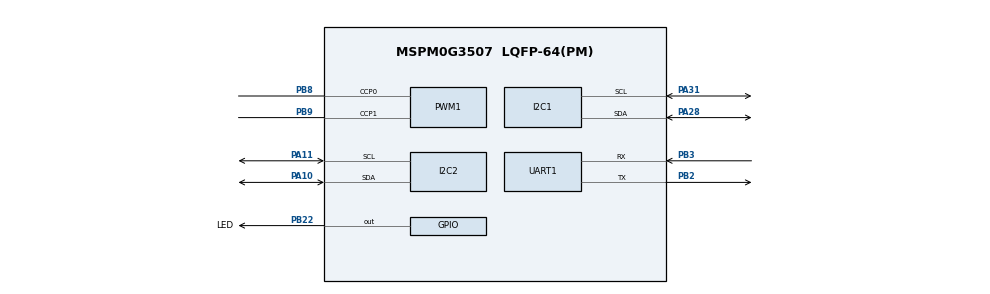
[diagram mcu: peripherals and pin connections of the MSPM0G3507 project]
/**
 * MSPM0G3507 gimbal receiver.
 * PB8/PB9 output 50Hz servo PWM, PB3 receives K230 UART frames.
 */
//@cliArgs --device "MSPM0G350X" --package "LQFP-64(PM)" --part "Default"
//@v2CliArgs --device "MSPM0G3507" --package "LQFP-64(PM)"

const GPIO   = scripting.addModule("/ti/driverlib/GPIO", {}, false);
const GPIO1  = GPIO.addInstance();
const PWM    = scripting.addModule("/ti/driverlib/PWM", {}, false);
const PWM1   = PWM.addInstance();
const SYSCTL = scripting.addModule("/ti/driverlib/SYSCTL");
const I2C    = scripting.addModule("/ti/driverlib/I2C", {}, false);
const I2C1   = I2C.addInstance();
const I2C2   = I2C.addInstance();
const UART   = scripting.addModule("/ti/driverlib/UART", {}, false);
const UART1  = UART.addInstance();
const Board  = scripting.addModule("/ti/driverlib/Board", {}, false);

GPIO1.$name                         = "GPIO";
GPIO1.associatedPins[0].$name       = "LED";
GPIO1.associatedPins[0].pin.$assign = "PB22";

PWM1.$name                              = "SERVO_PWM";
PWM1.timerStartTimer                    = true;
PWM1.timerCount                         = 9999;
PWM1.clockPrescale                      = 64;
PWM1.peripheral.ccp0Pin.$assign         = "PB8";
PWM1.peripheral.ccp1Pin.$assign         = "PB9";
PWM1.PWM_CHANNEL_0.$name                = "ti_driverlib_pwm_PWMTimerCC0";
PWM1.PWM_CHANNEL_1.$name                = "ti_driverlib_pwm_PWMTimerCC1";
PWM1.ccp0PinConfig.$name                = "ti_driverlib_gpio_GPIOPinGeneric0";
PWM1.ccp0PinConfig.direction            = scripting.forceWrite("OUTPUT");
PWM1.ccp0PinConfig.hideOutputInversion  = scripting.forceWrite(false);
PWM1.ccp0PinConfig.onlyInternalResistor = scripting.forceWrite(false);
PWM1.ccp0PinConfig.passedPeripheralType = scripting.forceWrite("Digital");
PWM1.ccp1PinConfig.$name                = "ti_driverlib_gpio_GPIOPinGeneric1";
PWM1.ccp1PinConfig.direction            = scripting.forceWrite("OUTPUT");
PWM1.ccp1PinConfig.hideOutputInversion  = scripting.forceWrite(false);
PWM1.ccp1PinConfig.onlyInternalResistor = scripting.forceWrite(false);
PWM1.ccp1PinConfig.passedPeripheralType = scripting.forceWrite("Digital");

SYSCTL.forceDefaultClkConfig = true;

I2C1.$name                     = "I2C_OLED";
I2C1.peripheral.sdaPin.$assign = "PA28";
I2C1.peripheral.sclPin.$assign = "PA31";
I2C1.basicEnableController     = true;
I2C1.basicControllerBusSpeed   = 400000;
I2C1.advControllerTXFIFOTRIG   = "BYTES_1";
I2C1.sdaPinConfig.$name        = "ti_driverlib_gpio_GPIOPinGeneric4";
I2C1.sclPinConfig.$name        = "ti_driverlib_gpio_GPIOPinGeneric5";

I2C2.$name                     = "I2C_MPU";
I2C2.peripheral.sdaPin.$assign = "PA10";
I2C2.peripheral.sclPin.$assign = "PA11";
I2C2.basicEnableController     = true;
I2C2.basicControllerBusSpeed   = 400000;
I2C2.advControllerTXFIFOTRIG   = "BYTES_1";
I2C2.sdaPinConfig.$name        = "ti_driverlib_gpio_GPIOPinGeneric6";
I2C2.sclPinConfig.$name        = "ti_driverlib_gpio_GPIOPinGeneric7";

UART1.$name                            = "UART_K230";
UART1.targetBaudRate                   = 9600;
UART1.peripheral.rxPin.$assign         = "PB3";
UART1.peripheral.txPin.$assign         = "PB2";
UART1.txPinConfig.$name                = "ti_driverlib_gpio_GPIOPinGeneric2";
UART1.txPinConfig.direction            = scripting.forceWrite("OUTPUT");
UART1.txPinConfig.hideOutputInversion  = scripting.forceWrite(false);
UART1.txPinConfig.onlyInternalResistor = scripting.forceWrite(false);
UART1.txPinConfig.passedPeripheralType = scripting.forceWrite("Digital");
UART1.rxPinConfig.$name                = "ti_driverlib_gpio_GPIOPinGeneric3";
UART1.rxPinConfig.hideOutputInversion  = scripting.forceWrite(false);
UART1.rxPinConfig.onlyInternalResistor = scripting.forceWrite(false);
UART1.rxPinConfig.passedPeripheralType = scripting.forceWrite("Digital");

Board.peripheral.$suggestSolution          = "DEBUGSS";
Board.peripheral.swclkPin.$suggestSolution = "PA20";
Board.peripheral.swdioPin.$suggestSolution = "PA19";
PWM1.peripheral.$suggestSolution           = "TIMA0";
I2C1.peripheral.$suggestSolution           = "I2C0";
I2C2.peripheral.$suggestSolution           = "I2C1";
SYSCTL.peripheral.$suggestSolution         = "SYSCTL";
UART1.peripheral.$suggestSolution          = "UART3";
